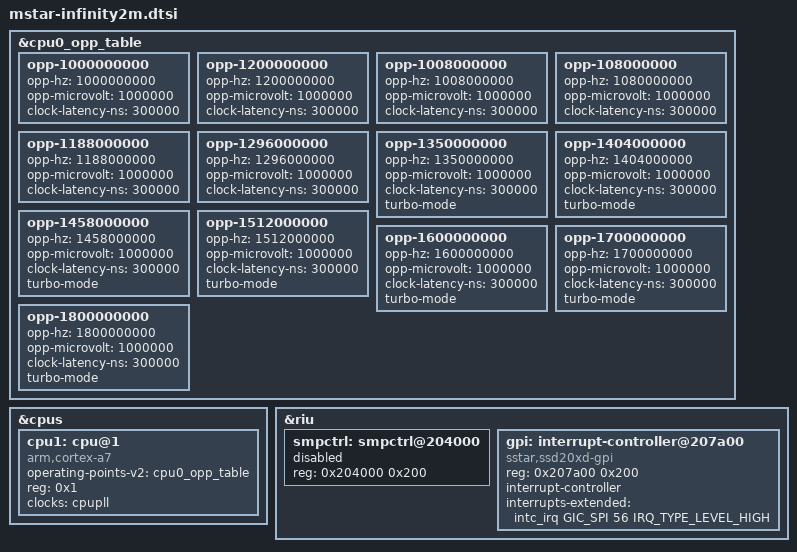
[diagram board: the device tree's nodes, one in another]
// SPDX-License-Identifier: GPL-2.0-or-later
/*
 * Copyright (c) 2020 thingy.jp.
 * Author: Daniel Palmer <daniel@thingy.jp>
 */

#include "mstar-infinity.dtsi"

&cpu0_opp_table {
		opp-1000000000 {
			opp-hz = /bits/ 64 <1000000000>;
			opp-microvolt = <1000000>;
			clock-latency-ns = <300000>;
		};

		opp-1200000000 {
			opp-hz = /bits/ 64 <1200000000>;
			opp-microvolt = <1000000>;
			clock-latency-ns = <300000>;
		};
};

&cpus {
	cpu1: cpu@1 {
		device_type = "cpu";
		compatible = "arm,cortex-a7";
		operating-points-v2 = <&cpu0_opp_table>;
		reg = <0x1>;
		clocks = <&cpupll>;
		clock-names = "cpuclk";
	};
};

&cpu0_opp_table {
	opp-1008000000 {
		opp-hz = /bits/ 64 <1008000000>;
		opp-microvolt = <1000000>;
		clock-latency-ns = <300000>;
	};

	opp-108000000 {
		opp-hz = /bits/ 64 <1080000000>;
		opp-microvolt = <1000000>;
		clock-latency-ns = <300000>;
	};

	opp-1188000000 {
		opp-hz = /bits/ 64 <1188000000>;
		opp-microvolt = <1000000>;
		clock-latency-ns = <300000>;
	};

	opp-1296000000 {
		opp-hz = /bits/ 64 <1296000000>;
		opp-microvolt = <1000000>;
		clock-latency-ns = <300000>;
	};

	/* Overclock. Stable upto 1.8GHz */
	opp-1350000000 {
		opp-hz = /bits/ 64 <1350000000>;
		opp-microvolt = <1000000>;
		clock-latency-ns = <300000>;
		turbo-mode;
	};

	opp-1404000000 {
		opp-hz = /bits/ 64 <1404000000>;
		opp-microvolt = <1000000>;
		clock-latency-ns = <300000>;
		turbo-mode;
	};

	opp-1458000000 {
		opp-hz = /bits/ 64 <1458000000>;
		opp-microvolt = <1000000>;
		clock-latency-ns = <300000>;
		turbo-mode;
	};

	opp-1512000000 {
		opp-hz = /bits/ 64 <1512000000>;
		opp-microvolt = <1000000>;
		clock-latency-ns = <300000>;
		turbo-mode;
	};

	opp-1600000000 {
		opp-hz = /bits/ 64 <1600000000>;
		opp-microvolt = <1000000>;
		clock-latency-ns = <300000>;
		turbo-mode;
	};

	opp-1700000000 {
		opp-hz = /bits/ 64 <1700000000>;
		opp-microvolt = <1000000>;
		clock-latency-ns = <300000>;
		turbo-mode;
	};

	opp-1800000000 {
		opp-hz = /bits/ 64 <1800000000>;
		opp-microvolt = <1000000>;
		clock-latency-ns = <300000>;
		turbo-mode;
	};
};

&riu {
	smpctrl: smpctrl@204000 {
		reg = <0x204000 0x200>;
		status = "disabled";
	};

	gpi: interrupt-controller@207a00 {
		compatible = "sstar,ssd20xd-gpi";
		reg = <0x207a00 0x200>;
		#interrupt-cells = <2>;
		interrupt-controller;
		interrupts-extended = <&intc_irq GIC_SPI 56 IRQ_TYPE_LEVEL_HIGH>;
	};
};
